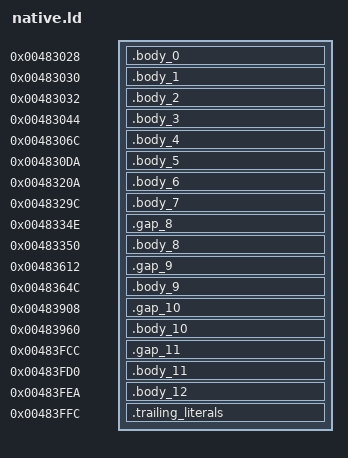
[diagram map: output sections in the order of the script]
ENTRY(native_lv_out_buffer)
SECTIONS {
.body_0 0x483028 : {*(.body_0)}
.body_1 0x483030 : {*(.body_1)}
.body_2 0x483032 : {*(.body_2)}
.body_3 0x483044 : {*(.body_3)}
.body_4 0x48306c : {*(.body_4)}
.body_5 0x4830da : {*(.body_5)}
.body_6 0x48320a : {*(.body_6)}
.body_7 0x48329c : {*(.body_7)}
.gap_8 0x48334e : {*(.gap_8)}
.body_8 0x483350 : {*(.body_8)}
.gap_9 0x483612 : {*(.gap_9)}
.body_9 0x48364c : {*(.body_9)}
.gap_10 0x483908 : {*(.gap_10)}
.body_10 0x483960 : {*(.body_10)}
.gap_11 0x483fcc : {*(.gap_11)}
.body_11 0x483fd0 : {*(.body_11)}
.body_12 0x483fea : {*(.body_12)}
.trailing_literals 0x483ffc : {*(.trailing_literals)}
}
